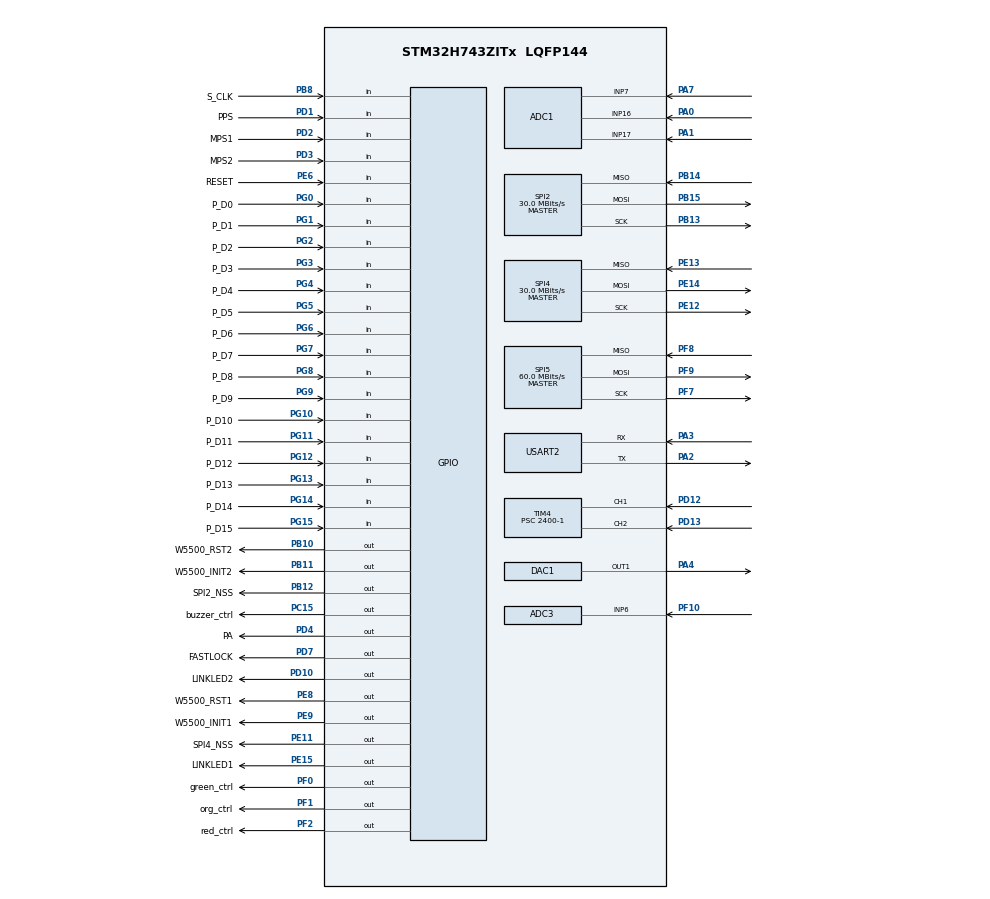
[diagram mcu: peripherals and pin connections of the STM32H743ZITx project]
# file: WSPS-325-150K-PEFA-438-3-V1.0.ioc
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ADC1.Channel-0\#ChannelRegularConversion=ADC_CHANNEL_16
ADC1.NbrOfConversionFlag=1
ADC1.OffsetNumber-0\#ChannelRegularConversion=ADC_OFFSET_NONE
ADC1.OffsetSignedSaturation-0\#ChannelRegularConversion=DISABLE
ADC1.Rank-0\#ChannelRegularConversion=1
ADC1.SamplingTime-0\#ChannelRegularConversion=ADC_SAMPLETIME_1CYCLE_5
ADC1.master=1
ADC3.Channel-0\#ChannelRegularConversion=ADC_CHANNEL_6
ADC3.NbrOfConversionFlag=1
ADC3.OffsetNumber-0\#ChannelRegularConversion=ADC_OFFSET_NONE
ADC3.OffsetSignedSaturation-0\#ChannelRegularConversion=DISABLE
ADC3.Rank-0\#ChannelRegularConversion=1
ADC3.SamplingTime-0\#ChannelRegularConversion=ADC_SAMPLETIME_1CYCLE_5
DAC1.DAC_Channel-DAC_OUT1=DAC_CHANNEL_1
Dma.ADC1.2.Direction=DMA_PERIPH_TO_MEMORY
Dma.ADC1.2.EventEnable=DISABLE
Dma.ADC1.2.FIFOMode=DMA_FIFOMODE_DISABLE
Dma.ADC1.2.Instance=DMA1_Stream2
Dma.ADC1.2.MemDataAlignment=DMA_MDATAALIGN_HALFWORD
Dma.ADC1.2.MemInc=DMA_MINC_ENABLE
Dma.ADC1.2.Mode=DMA_NORMAL
Dma.ADC1.2.PeriphDataAlignment=DMA_PDATAALIGN_HALFWORD
Dma.ADC1.2.PeriphInc=DMA_PINC_DISABLE
Dma.ADC1.2.Polarity=HAL_DMAMUX_REQ_GEN_RISING
Dma.ADC1.2.Priority=DMA_PRIORITY_LOW
Dma.ADC1.2.RequestNumber=1
Dma.ADC1.2.SignalID=NONE
Dma.ADC1.2.SyncEnable=DISABLE
Dma.ADC1.2.SyncPolarity=HAL_DMAMUX_SYNC_NO_EVENT
Dma.ADC1.2.SyncRequestNumber=1
Dma.ADC1.2.SyncSignalID=NONE
Dma.ADC3.3.Direction=DMA_PERIPH_TO_MEMORY
Dma.ADC3.3.EventEnable=DISABLE
Dma.ADC3.3.FIFOMode=DMA_FIFOMODE_DISABLE
Dma.ADC3.3.Instance=DMA1_Stream3
Dma.ADC3.3.MemDataAlignment=DMA_MDATAALIGN_HALFWORD
Dma.ADC3.3.MemInc=DMA_MINC_ENABLE
Dma.ADC3.3.Mode=DMA_NORMAL
Dma.ADC3.3.PeriphDataAlignment=DMA_PDATAALIGN_HALFWORD
Dma.ADC3.3.PeriphInc=DMA_PINC_DISABLE
Dma.ADC3.3.Polarity=HAL_DMAMUX_REQ_GEN_RISING
Dma.ADC3.3.Priority=DMA_PRIORITY_LOW
Dma.ADC3.3.RequestNumber=1
Dma.ADC3.3.SignalID=NONE
Dma.ADC3.3.SyncEnable=DISABLE
Dma.ADC3.3.SyncPolarity=HAL_DMAMUX_SYNC_NO_EVENT
Dma.ADC3.3.SyncRequestNumber=1
Dma.ADC3.3.SyncSignalID=NONE
Dma.Request0=USART2_RX
Dma.Request1=USART2_TX
Dma.Request2=ADC1
Dma.Request3=ADC3
Dma.USART2_RX.0.Direction=DMA_PERIPH_TO_MEMORY
Dma.USART2_RX.0.EventEnable=DISABLE
Dma.USART2_RX.0.FIFOMode=DMA_FIFOMODE_DISABLE
Dma.USART2_RX.0.Instance=DMA1_Stream0
Dma.USART2_RX.0.MemDataAlignment=DMA_MDATAALIGN_BYTE
Dma.USART2_RX.0.MemInc=DMA_MINC_ENABLE
Dma.USART2_RX.0.Mode=DMA_NORMAL
Dma.USART2_RX.0.PeriphDataAlignment=DMA_PDATAALIGN_BYTE
Dma.USART2_RX.0.PeriphInc=DMA_PINC_DISABLE
Dma.USART2_RX.0.Polarity=HAL_DMAMUX_REQ_GEN_RISING
Dma.USART2_RX.0.Priority=DMA_PRIORITY_LOW
Dma.USART2_RX.0.RequestNumber=1
Dma.USART2_RX.0.SignalID=NONE
Dma.USART2_RX.0.SyncEnable=DISABLE
Dma.USART2_RX.0.SyncPolarity=HAL_DMAMUX_SYNC_NO_EVENT
Dma.USART2_RX.0.SyncRequestNumber=1
Dma.USART2_RX.0.SyncSignalID=NONE
Dma.USART2_TX.1.Direction=DMA_MEMORY_TO_PERIPH
Dma.USART2_TX.1.EventEnable=DISABLE
Dma.USART2_TX.1.FIFOMode=DMA_FIFOMODE_DISABLE
Dma.USART2_TX.1.Instance=DMA1_Stream1
Dma.USART2_TX.1.MemDataAlignment=DMA_MDATAALIGN_BYTE
Dma.USART2_TX.1.MemInc=DMA_MINC_ENABLE
Dma.USART2_TX.1.Mode=DMA_NORMAL
Dma.USART2_TX.1.PeriphDataAlignment=DMA_PDATAALIGN_BYTE
Dma.USART2_TX.1.PeriphInc=DMA_PINC_DISABLE
Dma.USART2_TX.1.Polarity=HAL_DMAMUX_REQ_GEN_RISING
Dma.USART2_TX.1.Priority=DMA_PRIORITY_LOW
Dma.USART2_TX.1.RequestNumber=1
Dma.USART2_TX.1.SignalID=NONE
Dma.USART2_TX.1.SyncEnable=DISABLE
Dma.USART2_TX.1.SyncPolarity=HAL_DMAMUX_SYNC_NO_EVENT
Dma.USART2_TX.1.SyncRequestNumber=1
Dma.USART2_TX.1.SyncSignalID=NONE
Mcu.Family=STM32H7
Mcu.Name=STM32H743ZITx
Mcu.Package=LQFP144
NVIC.DMA1_Stream0_IRQn=true\:3\:0\:true\:false\:true\:false\:true
NVIC.DMA1_Stream1_IRQn=true\:3\:0\:true\:false\:true\:false\:true
NVIC.DMA1_Stream2_IRQn=true\:0\:0\:false\:false\:true\:false\:true
NVIC.DMA1_Stream3_IRQn=true\:0\:0\:false\:false\:true\:false\:true
NVIC.PriorityGroup=NVIC_PRIORITYGROUP_2
NVIC.TIM4_IRQn=true\:3\:1\:true\:false\:true\:true\:true
NVIC.USART2_IRQn=true\:1\:0\:true\:false\:true\:true\:true
PA0.Mode=IN16-Single-Ended
PA0.Signal=ADC1_INP16
PA1.Mode=IN17-Single-Ended
PA1.Signal=ADC1_INP17
PA13\ (JTMS/SWDIO).Mode=JTAG_5_pins
PA13\ (JTMS/SWDIO).Signal=DEBUG_JTMS-SWDIO
PA14\ (JTCK/SWCLK).Mode=JTAG_5_pins
PA14\ (JTCK/SWCLK).Signal=DEBUG_JTCK-SWCLK
PA15\ (JTDI).Mode=JTAG_5_pins
PA15\ (JTDI).Signal=DEBUG_JTDI
PA2.Mode=Asynchronous
PA2.Signal=USART2_TX
PA3.Mode=Asynchronous
PA3.Signal=USART2_RX
PA4.Signal=COMP_DAC11_group
PA7.Signal=ADCx_INP7
PB10.GPIO_Label=W5500_RST2
PB10.Signal=GPIO_Output
PB11.GPIO_Label=W5500_INIT2
PB11.Signal=GPIO_Output
PB12.GPIO_Label=SPI2_NSS
PB12.Signal=GPIO_Output
PB13.Mode=Full_Duplex_Master
PB13.Signal=SPI2_SCK
PB14.Mode=Full_Duplex_Master
PB14.Signal=SPI2_MISO
PB15.Mode=Full_Duplex_Master
PB15.Signal=SPI2_MOSI
PB3\ (JTDO/TRACESWO).Mode=JTAG_5_pins
PB3\ (JTDO/TRACESWO).Signal=DEBUG_JTDO-SWO
PB4\ (NJTRST).Mode=JTAG_5_pins
PB4\ (NJTRST).Signal=DEBUG_JTRST
PB8.GPIO_Label=S_CLK
PB8.Signal=GPIO_Input
PC15-OSC32_OUT\ (OSC32_OUT).GPIO_Label=buzzer_ctrl
PC15-OSC32_OUT\ (OSC32_OUT).Signal=GPIO_Output
PD1.GPIO_Label=PPS
PD1.Signal=GPIO_Input
PD10.GPIO_Label=LINKLED2
PD10.Signal=GPIO_Output
PD12.Signal=S_TIM4_CH1
PD13.Signal=S_TIM4_CH2
PD2.GPIO_Label=MPS1
PD2.Signal=GPIO_Input
PD3.GPIO_Label=MPS2
PD3.Signal=GPIO_Input
PD4.GPIO_Label=PA
PD4.Signal=GPIO_Output
PD7.GPIO_Label=FASTLOCK
PD7.Signal=GPIO_Output
PE11.GPIO_Label=SPI4_NSS
PE11.Signal=GPIO_Output
PE12.Mode=Full_Duplex_Master
PE12.Signal=SPI4_SCK
PE13.Mode=Full_Duplex_Master
PE13.Signal=SPI4_MISO
PE14.Mode=Full_Duplex_Master
PE14.Signal=SPI4_MOSI
PE15.GPIO_Label=LINKLED1
PE15.Signal=GPIO_Output
PE6.GPIO_Label=RESET
PE6.Signal=GPIO_Input
PE8.GPIO_Label=W5500_RST1
PE8.Signal=GPIO_Output
PE9.GPIO_Label=W5500_INIT1
PE9.Signal=GPIO_Output
PF0.GPIO_Label=green_ctrl
PF0.Signal=GPIO_Output
PF1.GPIO_Label=org_ctrl
PF1.Signal=GPIO_Output
PF10.Mode=IN6-Single-Ended
PF10.Signal=ADC3_INP6
PF2.GPIO_Label=red_ctrl
PF2.Signal=GPIO_Output
PF7.Mode=Full_Duplex_Master
PF7.Signal=SPI5_SCK
PF8.Mode=Full_Duplex_Master
PF8.Signal=SPI5_MISO
PF9.Mode=Full_Duplex_Master
PF9.Signal=SPI5_MOSI
PG0.GPIO_Label=P_D0
PG0.Signal=GPIO_Input
PG1.GPIO_Label=P_D1
PG1.Signal=GPIO_Input
PG10.GPIO_Label=P_D10
PG10.Signal=GPIO_Input
PG11.GPIO_Label=P_D11
PG11.Signal=GPIO_Input
PG12.GPIO_Label=P_D12
PG12.Signal=GPIO_Input
PG13.GPIO_Label=P_D13
PG13.Signal=GPIO_Input
PG14.GPIO_Label=P_D14
PG14.Signal=GPIO_Input
PG15.GPIO_Label=P_D15
PG15.Signal=GPIO_Input
PG2.GPIO_Label=P_D2
PG2.Signal=GPIO_Input
PG3.GPIO_Label=P_D3
PG3.Signal=GPIO_Input
PG4.GPIO_Label=P_D4
PG4.Signal=GPIO_Input
PG5.GPIO_Label=P_D5
PG5.Signal=GPIO_Input
PG6.GPIO_Label=P_D6
PG6.Signal=GPIO_Input
PG7.GPIO_Label=P_D7
PG7.Signal=GPIO_Input
PG8.GPIO_Label=P_D8
PG8.Signal=GPIO_Input
PG9.GPIO_Label=P_D9
PG9.Signal=GPIO_Input
PH0-OSC_IN\ (PH0).Mode=HSE-External-Clock-Source
PH0-OSC_IN\ (PH0).Signal=RCC_OSC_IN
ProjectManager.HeapSize=0x200
ProjectManager.StackSize=0x400
ProjectManager.TargetToolchain=MDK-ARM V5.32
RCC.ADCFreq_Value=30000000
RCC.APB1Freq_Value=120000000
RCC.APB2Freq_Value=120000000
RCC.APB3Freq_Value=120000000
RCC.APB4Freq_Value=120000000
RCC.CortexFreq_Value=480000000
RCC.D1PPRE=RCC_APB3_DIV2
RCC.D2PPRE1=RCC_APB1_DIV2
RCC.D2PPRE2=RCC_APB2_DIV2
RCC.D3PPRE=RCC_APB4_DIV2
RCC.DIVM1=10
RCC.DIVM2=40
RCC.DIVM3=10
RCC.DIVN1=240
RCC.DIVN2=240
RCC.DIVN3=240
RCC.DIVP2=8
RCC.DIVP3=8
RCC.DIVQ1=8
RCC.DIVQ2=8
RCC.DIVQ3=8
RCC.DIVR1=8
RCC.HCLKFreq_Value=240000000
RCC.HPRE=RCC_HCLK_DIV2
RCC.HSE_VALUE=40000000
RCC.PLLSourceVirtual=RCC_PLLSOURCE_HSE
RCC.SYSCLKFreq_VALUE=480000000
RCC.SYSCLKSource=RCC_SYSCLKSOURCE_PLLCLK
RCC.USBFreq_Value=120000000
SH.ADCx_INP7.0=ADC1_INP7,IN7-Single-Ended
SH.COMP_DAC11_group.0=DAC1_OUT1,DAC_OUT1
SH.S_TIM4_CH1.0=TIM4_CH1,TriggerSource_TI1FP1
SH.S_TIM4_CH2.0=TIM4_CH2,Input_Capture2_from_TI2
SPI2.BaudRatePrescaler=SPI_BAUDRATEPRESCALER_4
SPI2.CLKPhase=SPI_PHASE_2EDGE
SPI2.CLKPolarity=SPI_POLARITY_HIGH
SPI2.CalculateBaudRate=30.0 MBits/s
SPI2.DataSize=SPI_DATASIZE_8BIT
SPI2.Direction=SPI_DIRECTION_2LINES
SPI2.Mode=SPI_MODE_MASTER
SPI2.NSSPMode=SPI_NSS_PULSE_DISABLE
SPI2.VirtualType=VM_MASTER
SPI4.BaudRatePrescaler=SPI_BAUDRATEPRESCALER_4
SPI4.CLKPhase=SPI_PHASE_2EDGE
SPI4.CLKPolarity=SPI_POLARITY_HIGH
SPI4.CalculateBaudRate=30.0 MBits/s
SPI4.DataSize=SPI_DATASIZE_8BIT
SPI4.Direction=SPI_DIRECTION_2LINES
SPI4.Mode=SPI_MODE_MASTER
SPI4.NSSPMode=SPI_NSS_PULSE_DISABLE
SPI4.VirtualType=VM_MASTER
SPI5.CalculateBaudRate=60.0 MBits/s
SPI5.Direction=SPI_DIRECTION_2LINES
SPI5.Mode=SPI_MODE_MASTER
SPI5.VirtualType=VM_MASTER
TIM4.AutoReloadPreload=TIM_AUTORELOAD_PRELOAD_DISABLE
TIM4.Channel-Input_Capture1_from_TI2_63=TIM_CHANNEL_1
TIM4.Channel-Input_Capture2_from_TI2=TIM_CHANNEL_2
TIM4.ICPolarity_CH2=TIM_INPUTCHANNELPOLARITY_FALLING
TIM4.Prescaler=2400-1
USART2.DMADisableonRxErrorParam=ADVFEATURE_DMA_DISABLEONRXERROR
USART2.OverrunDisableParam=ADVFEATURE_OVERRUN_DISABLE
USART2.VirtualMode-Asynchronous=VM_ASYNC
VP_TIM4_VS_ClockSourceINT.Mode=Internal
VP_TIM4_VS_ControllerModeReset.Mode=Reset Mode
VP_TIM4_VS_indirect_ch2.Mode=Input_Capture1_from_TI2_63
board=custom

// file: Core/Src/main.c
/* USER CODE BEGIN Header */
/**
  ******************************************************************************
  * @file           : main.c
  * @brief          : Main program body
  ******************************************************************************
  * @attention
  *
  * <h2><center>&copy; Copyright (c) 2022 STMicroelectronics.
  * All rights reserved.</center></h2>
  *
  * This software component is licensed by ST under BSD 3-Clause license,
  * the "License"; You may not use this file except in compliance with the
  * License. You may obtain a copy of the License at:
  *                        opensource.org/licenses/BSD-3-Clause
  *
  ******************************************************************************
  */
/* USER CODE END Header */
#include "main.h"
#include "adc.h"
#include "dac.h"
#include "dma.h"
#include "spi.h"
#include "tim.h"
#include "usart.h"
#include "gpio.h"

/* USER CODE BEGIN Includes */

#include "../../App/task.h"
#include "../../App/tcp.h"
#include "../../App/udp.h"
#include "../../App/lcd_rs232.h"
/* USER CODE END Includes */

void SystemClock_Config(void);
void PeriphCommonClock_Config(void);

int main(void)
{

  /* MCU Configuration--------------------------------------------------------*/

  /* Reset of all peripherals, Initializes the Flash interface and the Systick. */
  HAL_Init();

  /* Configure the system clock */
  SystemClock_Config();

/* Configure the peripherals common clocks */
  PeriphCommonClock_Config();

  /* Initialize all configured peripherals */
  MX_GPIO_Init();
  MX_SPI2_Init();
  MX_SPI4_Init();
  MX_ADC1_Init();
  MX_DAC1_Init();
  MX_SPI5_Init();
  MX_USART2_UART_Init();
  MX_DMA_Init();
  MX_TIM4_Init();
  MX_ADC3_Init();
  /* USER CODE BEGIN 2 */
  Device_Init();
  /* USER CODE END 2 */

  /* Infinite loop */
  while (1)
  {

    /* USER CODE BEGIN 3 */
      /*灯控制*/
      Task_TCP();   /*与工控机通信*/
      Task_UDP();
      Task_Write_Modbus();
      Task_Control();
      Task_Ads8411_Receive_Data();
      Task_Get_temp();
      /*告警*/
      /*显示屏*/
      /*ADC/DAC*/
  }
  /* USER CODE END 3 */
}

void SystemClock_Config(void)
{
  RCC_OscInitTypeDef RCC_OscInitStruct = {0};
  RCC_ClkInitTypeDef RCC_ClkInitStruct = {0};

  /** Supply configuration update enable
  */
  HAL_PWREx_ConfigSupply(PWR_LDO_SUPPLY);
  /** Configure the main internal regulator output voltage
  */
  __HAL_PWR_VOLTAGESCALING_CONFIG(PWR_REGULATOR_VOLTAGE_SCALE0);

  while(!__HAL_PWR_GET_FLAG(PWR_FLAG_VOSRDY)) {}
  /** Macro to configure the PLL clock source
  */
  __HAL_RCC_PLL_PLLSOURCE_CONFIG(RCC_PLLSOURCE_HSE);
  /** Initializes the RCC Oscillators according to the specified parameters
  * in the RCC_OscInitTypeDef structure.
  */
  RCC_OscInitStruct.OscillatorType = RCC_OSCILLATORTYPE_HSE;
  RCC_OscInitStruct.HSEState = RCC_HSE_BYPASS;
  RCC_OscInitStruct.PLL.PLLState = RCC_PLL_ON;
  RCC_OscInitStruct.PLL.PLLSource = RCC_PLLSOURCE_HSE;
  RCC_OscInitStruct.PLL.PLLM = 10;
  RCC_OscInitStruct.PLL.PLLN = 240;
  RCC_OscInitStruct.PLL.PLLP = 2;
  RCC_OscInitStruct.PLL.PLLQ = 8;
  RCC_OscInitStruct.PLL.PLLR = 8;
  RCC_OscInitStruct.PLL.PLLRGE = RCC_PLL1VCIRANGE_2;
  RCC_OscInitStruct.PLL.PLLVCOSEL = RCC_PLL1VCOWIDE;
  RCC_OscInitStruct.PLL.PLLFRACN = 0;
  if (HAL_RCC_OscConfig(&RCC_OscInitStruct) != HAL_OK)
  {
    Error_Handler();
  }
  /** Initializes the CPU, AHB and APB buses clocks
  */
  RCC_ClkInitStruct.ClockType = RCC_CLOCKTYPE_HCLK|RCC_CLOCKTYPE_SYSCLK
                              |RCC_CLOCKTYPE_PCLK1|RCC_CLOCKTYPE_PCLK2
                              |RCC_CLOCKTYPE_D3PCLK1|RCC_CLOCKTYPE_D1PCLK1;
  RCC_ClkInitStruct.SYSCLKSource = RCC_SYSCLKSOURCE_PLLCLK;
  RCC_ClkInitStruct.SYSCLKDivider = RCC_SYSCLK_DIV1;
  RCC_ClkInitStruct.AHBCLKDivider = RCC_HCLK_DIV2;
  RCC_ClkInitStruct.APB3CLKDivider = RCC_APB3_DIV2;
  RCC_ClkInitStruct.APB1CLKDivider = RCC_APB1_DIV2;
  RCC_ClkInitStruct.APB2CLKDivider = RCC_APB2_DIV2;
  RCC_ClkInitStruct.APB4CLKDivider = RCC_APB4_DIV2;

  if (HAL_RCC_ClockConfig(&RCC_ClkInitStruct, FLASH_LATENCY_4) != HAL_OK)
  {
    Error_Handler();
  }
}

void PeriphCommonClock_Config(void)
{
  RCC_PeriphCLKInitTypeDef PeriphClkInitStruct = {0};

  /** Initializes the peripherals clock
  */
  PeriphClkInitStruct.PeriphClockSelection = RCC_PERIPHCLK_ADC;
  PeriphClkInitStruct.PLL2.PLL2M = 40;
  PeriphClkInitStruct.PLL2.PLL2N = 240;
  PeriphClkInitStruct.PLL2.PLL2P = 8;
  PeriphClkInitStruct.PLL2.PLL2Q = 8;
  PeriphClkInitStruct.PLL2.PLL2R = 2;
  PeriphClkInitStruct.PLL2.PLL2RGE = RCC_PLL2VCIRANGE_0;
  PeriphClkInitStruct.PLL2.PLL2VCOSEL = RCC_PLL2VCOWIDE;
  PeriphClkInitStruct.PLL2.PLL2FRACN = 0;
  PeriphClkInitStruct.AdcClockSelection = RCC_ADCCLKSOURCE_PLL2;
  if (HAL_RCCEx_PeriphCLKConfig(&PeriphClkInitStruct) != HAL_OK)
  {
    Error_Handler();
  }
}

void Error_Handler(void)
{
  __disable_irq();
  while (1)
  {
  }
}

/************************ (C) COPYRIGHT STMicroelectronics *****END OF FILE****/
